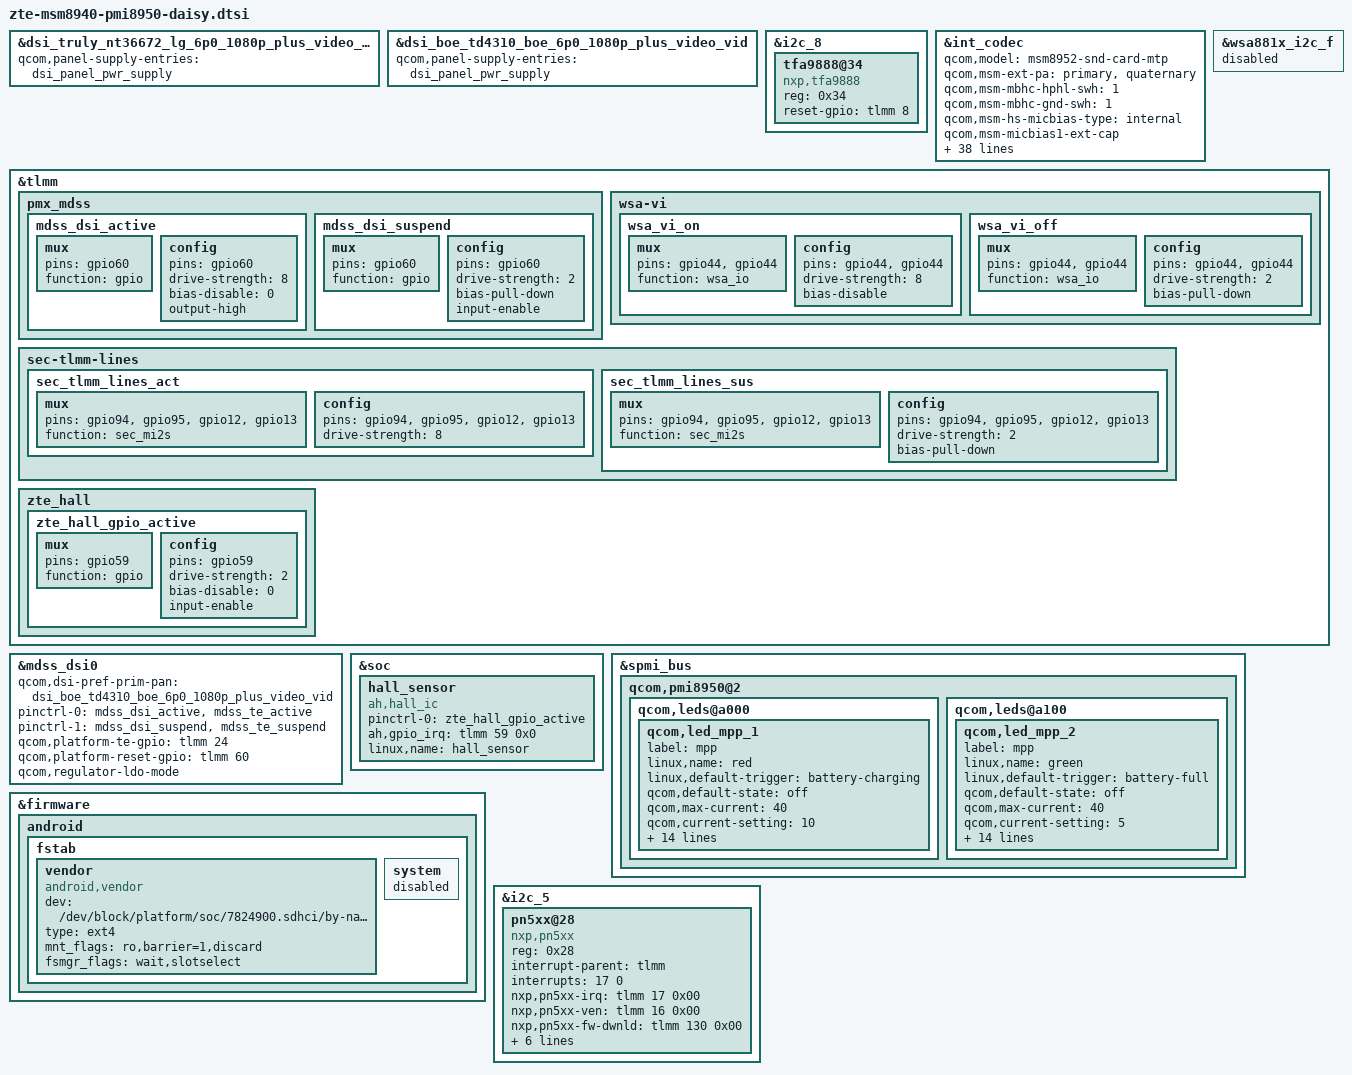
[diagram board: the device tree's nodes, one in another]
/*
 * Copyright (c) 2016, The Linux Foundation. All rights reserved.
 *
 * This program is free software; you can redistribute it and/or modify
 * it under the terms of the GNU General Public License version 2 and
 * only version 2 as published by the Free Software Foundation.
 *
 * This program is distributed in the hope that it will be useful,
 * but WITHOUT ANY WARRANTY; without even the implied warranty of
 * MERCHANTABILITY or FITNESS FOR A PARTICULAR PURPOSE.  See the
 * GNU General Public License for more details.
 */

#include "touch-key-backlight-daisy.dtsi"
#include "dsi-panel-zte-truly-nt36672-lg-6p0-1080p-plus-video.dtsi"
#include "dsi-panel-zte-boe-td4310-boe-6p0-1080p-plus-video.dtsi"
#include "msm8940-camera-sensor-zte-daisy.dtsi"

&dsi_truly_nt36672_lg_6p0_1080p_plus_video_vid {
	qcom,panel-supply-entries = <&dsi_panel_pwr_supply>;
};

&dsi_boe_td4310_boe_6p0_1080p_plus_video_vid {
	qcom,panel-supply-entries = <&dsi_panel_pwr_supply>;

};

&i2c_8 {
	tfa9888@34 {
		compatible = "nxp,tfa9888";
		reg = <0x34>;
		reset-gpio = <&tlmm 8 0x0>;
	};
};

&int_codec {
	qcom,model = "msm8952-snd-card-mtp";
	qcom,msm-ext-pa = "primary","quaternary";
	/* qcom,cdc-us-euro-gpios = <&tlmm 63 0>; */
	qcom,msm-mbhc-hphl-swh = <1>;
	qcom,msm-mbhc-gnd-swh = <1>;
	qcom,msm-hs-micbias-type = "internal";
	qcom,msm-micbias1-ext-cap;

	qcom,msm-gpios =
		"pri_i2s",
		"us_eu_gpio",
		"quat_i2s";
	qcom,pinctrl-names =
		"all_off",
		"pri_i2s_act",
		"us_eu_gpio_act",
		"pri_i2s_us_eu_gpio_act",
		"quat_act",
		"quat_pri_i2s_act",
		"quat_us_eu_gpio_act",
		"quat_us_eu_gpio_pri_i2s_act";
	pinctrl-names =
		"all_off",
		"pri_i2s_act",
		"us_eu_gpio_act",
		"pri_i2s_us_eu_gpio_act",
		"quat_act",
		"quat_pri_i2s_act",
		"quat_us_eu_gpio_act",
		"quat_us_eu_gpio_pri_i2s_act";
	pinctrl-0 = <&cdc_pdm_lines_sus &sec_tlmm_lines_sus
			&cdc_pdm_lines_2_sus &cross_conn_det_sus
			&pri_tlmm_lines_sus &pri_tlmm_ws_sus>;
	pinctrl-1 = <&cdc_pdm_lines_act &sec_tlmm_lines_sus
			&cdc_pdm_lines_2_act &cross_conn_det_sus
			&pri_tlmm_lines_sus &pri_tlmm_ws_sus>;
	pinctrl-2 = <&cdc_pdm_lines_sus &sec_tlmm_lines_sus
			&cdc_pdm_lines_2_sus &cross_conn_det_act
			&pri_tlmm_lines_sus &pri_tlmm_ws_sus>;
	pinctrl-3 = <&cdc_pdm_lines_act &sec_tlmm_lines_sus
			&cdc_pdm_lines_2_act &cross_conn_det_act
			&pri_tlmm_lines_sus &pri_tlmm_ws_sus>;
	pinctrl-4 = <&cdc_pdm_lines_sus
			&cdc_pdm_lines_2_sus &cross_conn_det_sus
			&sec_tlmm_lines_act>;
	pinctrl-5 = <&cdc_pdm_lines_act
			&cdc_pdm_lines_2_act &cross_conn_det_sus
			&sec_tlmm_lines_act>;
	pinctrl-6 = <&cdc_pdm_lines_sus
			&cdc_pdm_lines_2_sus &cross_conn_det_act
			&sec_tlmm_lines_act>;
	pinctrl-7 = <&cdc_pdm_lines_act
			&cdc_pdm_lines_2_act &cross_conn_det_act
			&sec_tlmm_lines_act>;

	asoc-codec = <&stub_codec>, <&pm8937_cajon_dig>, <&hdmi_dba>;
	asoc-codec-names = "msm-stub-codec.1", "cajon_codec","msm-hdmi-dba-codec-rx";
};

&wsa881x_i2c_f {
		status = "disable";
};

&tlmm {
		pmx_mdss: pmx_mdss {
			mdss_dsi_active: mdss_dsi_active {
				mux {
					pins = "gpio60";
					function = "gpio";
				};

				config {
					pins = "gpio60";
					drive-strength = <8>; /* 8 mA */
					bias-disable = <0>; /* no pull */
					output-high;
				};
			};
			mdss_dsi_suspend: mdss_dsi_suspend {
				mux {
					pins = "gpio60";
					function = "gpio";
				};

				config {
					pins = "gpio60";
					drive-strength = <2>; /* 2 mA */
					bias-pull-down; /* pull down */
					input-enable;
				};
			};
		};

		/* WSA VI sense */
		wsa-vi {
			wsa_vi_on: wsa_vi_on {
				mux {
					pins = "gpio44", "gpio44";
					function = "wsa_io";
				};

				config {
					pins = "gpio44", "gpio44";
					drive-strength = <8>; /* 8 MA */
					bias-disable; /* NO pull */
				};
			};

			wsa_vi_off: wsa_vi_off {
				mux {
					pins = "gpio44", "gpio44";
					function = "wsa_io";
				};

				config {
					pins = "gpio44", "gpio44";
					drive-strength = <2>; /* 2 MA */
					bias-pull-down;
				};
			};
		};

		sec-tlmm-lines {
			sec_tlmm_lines_act: sec_tlmm_lines_act {
				mux {
					pins = "gpio94", "gpio95", "gpio12", "gpio13";
					function = "sec_mi2s";

				};

				config {
					pins = "gpio94", "gpio95", "gpio12", "gpio13";
					drive-strength = <8>;
				};
			};

			sec_tlmm_lines_sus: sec_tlmm_lines_sus {
				mux {
					pins = "gpio94", "gpio95", "gpio12", "gpio13";
					function = "sec_mi2s";

				};

				config {
					pins = "gpio94", "gpio95", "gpio12", "gpio13";
					drive-strength = <2>;
					bias-pull-down;
				};
			};
		};

};


&mdss_dsi0 {
	qcom,dsi-pref-prim-pan = <&dsi_boe_td4310_boe_6p0_1080p_plus_video_vid>;
	pinctrl-names = "mdss_default", "mdss_sleep";
	pinctrl-0 = <&mdss_dsi_active &mdss_te_active>;
	pinctrl-1 = <&mdss_dsi_suspend &mdss_te_suspend>;
	/delete-property/ qcom,platform-enable-gpio;
	qcom,platform-te-gpio = <&tlmm 24 0>;
	qcom,platform-reset-gpio = <&tlmm 60 0>;
	/delete-property/ qcom,platform-bklight-en-gpio;
	qcom,regulator-ldo-mode;
};

&tlmm {
	zte_hall: zte_hall {
		zte_hall_gpio_active: zte_hall_gpio_active {
			mux {
				pins = "gpio59";
				function = "gpio";
			};
			config {
				pins = "gpio59";
				drive-strength = <2>; /* 2 mA */
				bias-disable = <0>; /* no pull */
				input-enable; /* input */
			};
		};
	};
};

&soc {

	/*added by zte_pm for hall*/
	hall_sensor {
		compatible = "ah,hall_ic";
		pinctrl-names = "zte_hall_gpio_active";
		pinctrl-0 = <&zte_hall_gpio_active>;
		ah,gpio_irq = <&tlmm 59 0x0>;
		linux,name = "hall_sensor";
	};
	/*end*/
};

&spmi_bus {

	qcom,pmi8950@2 {
		qcom,leds@a000 {
			status = "okay";
			qcom,led_mpp_1 {	/* red led */
				label = "mpp";
				linux,name = "red";
				linux,default-trigger = "battery-charging";
				qcom,default-state = "off";
				qcom,max-current = <40>;
				qcom,current-setting = <10>;
				qcom,id = <6>;
				#qcom,source-sel = <8>;
				qcom,source-sel = <11>; /* connect MPP to inverted DTEST2*/
				qcom,src-sel = <10>;

				qcom,mode-ctrl = <0x10>;
				qcom,pwm-channel = <0>;
				qcom,pwm-us = <1000>;
				qcom,vin-ctrl = <0x00>;
				qcom,duty-pcts = <50>;
				qcom,mode = "pwm";
				qcom,use-blink;
				pwms = <&pmi8950_pwm 0 0>;
				qcom,pwm-names = "red-led";
				zte,is-operator-sprint = "no";
			};
		};

		qcom,leds@a100 {
			status = "okay";
			qcom,led_mpp_2 {	/* green led */
				label = "mpp";
				linux,name = "green";		/* orgin is wled-backlight */
				linux,default-trigger = "battery-full";	/* org="bkl-trigger"; */
				qcom,default-state = "off";
				qcom,max-current = <40>;
				qcom,current-setting = <5>;	/*+ zte add +*/
				qcom,id = <6>;				/* in leds-qpnp.c enum QPNP_ID_LED_MPP(6) */
				#qcom,source-sel = <8>;		/* select power source, default 1 (enabled)(org=8) */
				qcom,source-sel = <10>; /* connect MPP to DTEST2*/
				qcom,src-sel = <10>;
				qcom,mode-ctrl = <0x60>;	/* operation mode, default 0x60 = Mode Sink (org=0x10)*/
				qcom,pwm-channel = <0>;
				qcom,pwm-us = <1000>;
				qcom,vin-ctrl = <0x00>;		/* select input source, 0 to 3 */
				qcom,duty-pcts = <50>;
				qcom,mode = "pwm";
				qcom,use-blink;
				pwms = <&pmi8950_pwm 0 0>;
				qcom,pwm-names = "green-led";
				zte,is-operator-sprint = "no";
			};
		};
	};
};
/*zte add for AB */
&firmware {
	android {
		fstab {
			vendor {
				compatible = "android,vendor";
				dev = "/dev/block/platform/soc/7824900.sdhci/by-name/vendor";
				type = "ext4";
				mnt_flags = "ro,barrier=1,discard";
				fsmgr_flags = "wait,slotselect";
				status = "ok";
			};
			system {
				status = "disabled";
			};
		};
	};
};


&i2c_5 {
	/delete-node/nq@28;
};

&i2c_5 {
	pn5xx@28{
		compatible = "nxp,pn5xx";
		reg = <0x28>;
		interrupt-parent = <&tlmm>;
		interrupts = <17 0>;
		nxp,pn5xx-irq = <&tlmm 17 0x00>;
		nxp,pn5xx-ven = <&tlmm 16 0x00>;
		nxp,pn5xx-fw-dwnld = <&tlmm 130 0x00>;
		//nxp,pn5xx-ese-pwr = <&tlmm 141 0x00>;
		//nxp,pn5xx-swp2-pwr = <&tlmm129 0x00>;
		//nxp,int_active_low = <0>;
		nxp,pn5xx-clkreq = <&pm8937_gpios 5 0x00>;
		nxp,clk-src = "BBCLK2";
		interrupt-names = "nfc_irq";
		pinctrl-names = "nfc_active","nfc_suspend";
		pinctrl-0 = <&nfc_int_active &nfc_disable_active>;
		pinctrl-1 = <&nfc_int_suspend &nfc_disable_suspend>;
		clocks = <&clock_gcc clk_bb_clk2_pin>;
		clock-names = "bb_clk2";
	};
};

